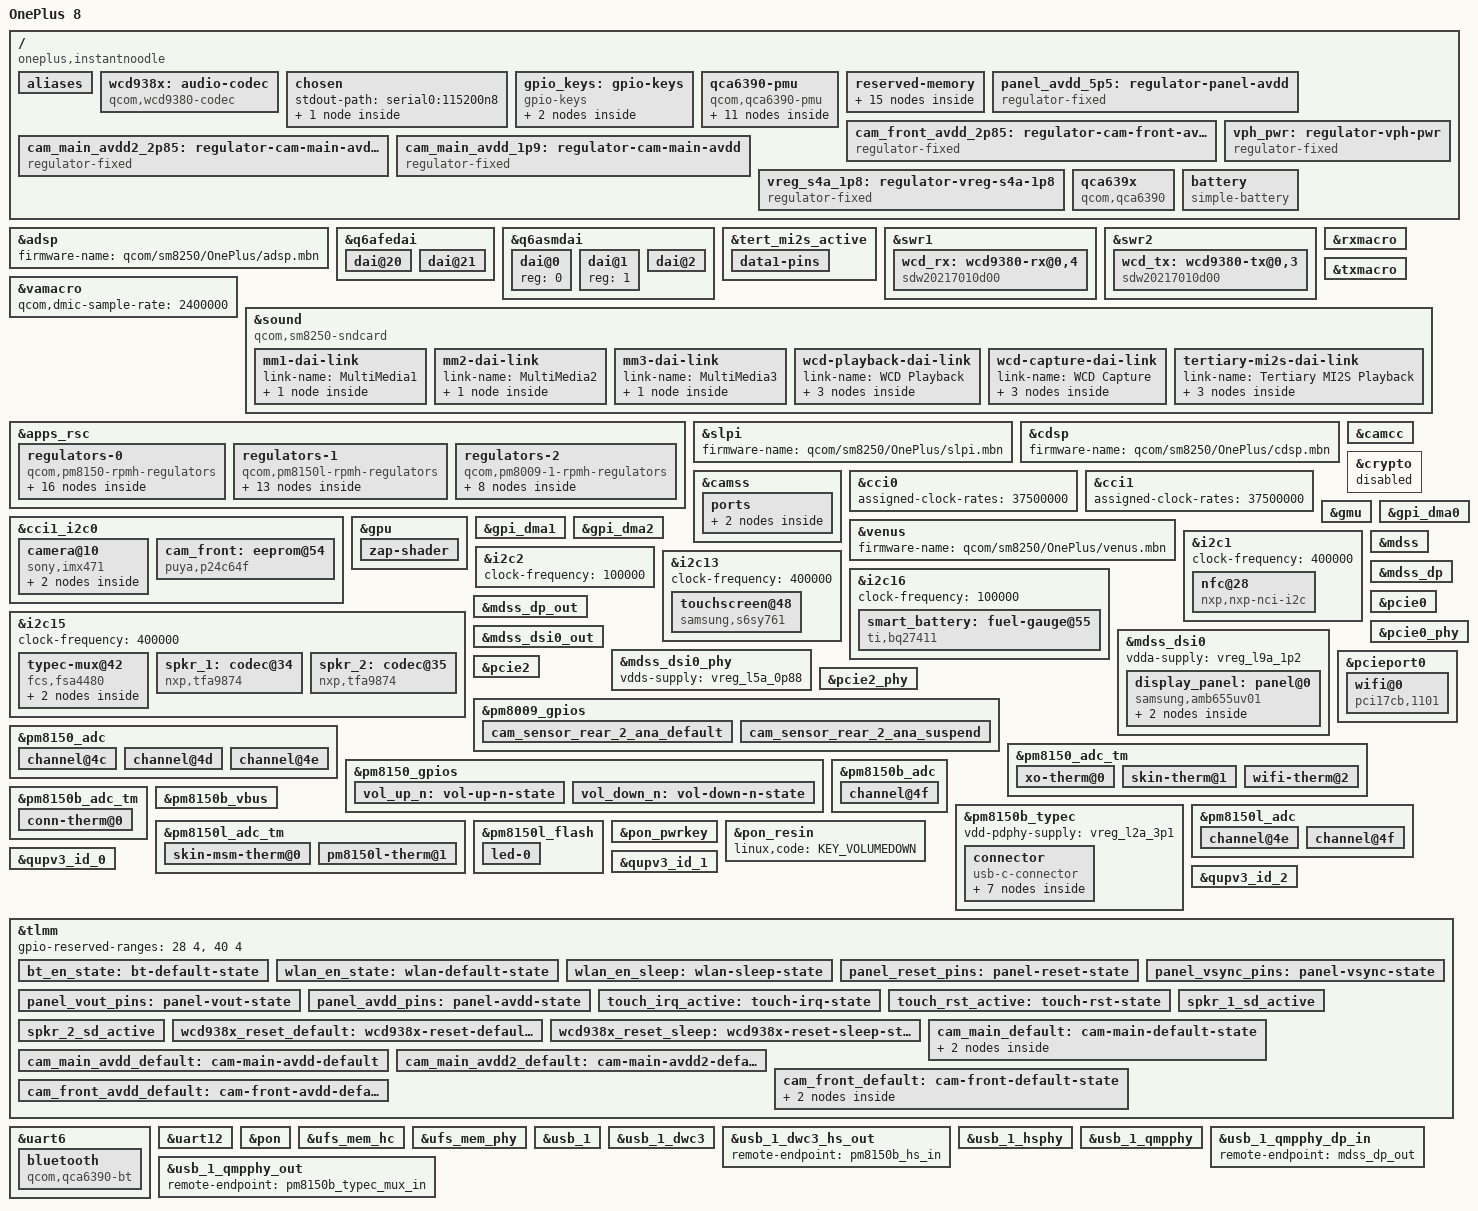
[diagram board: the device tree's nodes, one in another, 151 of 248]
// SPDX-License-Identifier: GPL-2.0 OR BSD-3-Clause
/*
 * Copyright (c) 2025, Xiaoou <xo666@postmarketos.org>
 */

/dts-v1/;

#include <dt-bindings/gpio/gpio.h>
#include <dt-bindings/arm/qcom,ids.h>
#include <dt-bindings/phy/phy.h>
#include <dt-bindings/leds/common.h>
#include <dt-bindings/media/video-interfaces.h>
#include <dt-bindings/regulator/qcom,rpmh-regulator.h>
#include <dt-bindings/sound/qcom,q6afe.h>
#include <dt-bindings/sound/qcom,q6asm.h>
#include <dt-bindings/sound/qcom,q6dsp-lpass-ports.h>
#include <dt-bindings/usb/pd.h>
#include "sm8250.dtsi"
#include "pm8150.dtsi"
#include "pm8150b.dtsi"
#include "pm8150l.dtsi"
#include "pm8009.dtsi"

/* removed_mem @ 0x80b00000 is bigger so we gotta shift everything up... */
/delete-node/ &removed_mem;
/delete-node/ &camera_mem;
/delete-node/ &wlan_mem;
/delete-node/ &ipa_fw_mem;
/delete-node/ &ipa_gsi_mem;
/delete-node/ &gpu_mem;
/delete-node/ &npu_mem;
/delete-node/ &video_mem;
/delete-node/ &cvp_mem;
/delete-node/ &cdsp_mem;
/delete-node/ &slpi_mem;
/delete-node/ &adsp_mem;
/delete-node/ &spss_mem;
/delete-node/ &cdsp_secure_heap;


/ {
	model = "OnePlus 8";
	compatible = "oneplus,instantnoodle", "qcom,kona", "qcom,sm8250";
	chassis-type = "handset";

	qcom,msm-id = <0x164 0x10000>, <0x164 0x20001>;
	qcom,board-id = <0x08 0x00>, <0x00 0x00>;

	aliases {
		serial0 = &uart12;
		serial1 = &uart6;
	};

	wcd938x: audio-codec {
		compatible = "qcom,wcd9380-codec";
		
		pinctrl-names = "default";
		pinctrl-0 = <&wcd938x_reset_default>;
		
		reset-gpios = <&tlmm 32 GPIO_ACTIVE_LOW>;

		vdd-buck-supply = <&vreg_s4a_1p8>;
		vdd-rxtx-supply = <&vreg_s4a_1p8>;
		vdd-io-supply = <&vreg_s4a_1p8>;
		vdd-mic-bias-supply = <&vreg_bob>;

		qcom,micbias1-microvolt = <1800000>;
		qcom,micbias2-microvolt = <1800000>;
		qcom,micbias3-microvolt = <1800000>;
		qcom,micbias4-microvolt = <1800000>;
		qcom,mbhc-buttons-vthreshold-microvolt = <75000 150000 237000 500000 500000 500000 500000 500000>;
		qcom,mbhc-headset-vthreshold-microvolt = <1700000>;
		qcom,mbhc-headphone-vthreshold-microvolt = <50000>;
		qcom,rx-device = <&wcd_rx>;
		qcom,tx-device = <&wcd_tx>;

		#sound-dai-cells = <1>;
	};

	chosen {
		#address-cells = <2>;
		#size-cells = <2>;
		ranges;

		stdout-path = "serial0:115200n8";

		framebuffer: framebuffer@9c000000 {
			compatible = "simple-framebuffer";
			reg = <0 0x9c000000 0 0x2300000>;
			width = <1080>;
			height = <2400>;
			stride = <(1080 * 4)>;
			format = "a8r8g8b8";
		};
	};

	gpio_keys: gpio-keys {
		compatible = "gpio-keys";

		vol-up {
			label = "Volume Up";
			gpios = <&pm8150_gpios 6 GPIO_ACTIVE_LOW>;
			linux,code = <KEY_VOLUMEUP>;
			debounce-interval = <15>;
			linux,can-disable;
			gpio-key,wakeup;
		};

		vol-down {
			label = "Volume Down";
			linux,code = <KEY_VOLUMEDOWN>;
			gpios = <&pm8150_gpios 7 GPIO_ACTIVE_LOW>;
			debounce-interval = <15>;
			linux,can-disable;
			gpio-key,wakeup;
		};
	};

	qca6390-pmu {
		compatible = "qcom,qca6390-pmu";

		pinctrl-names = "default";
		pinctrl-0 = <&bt_en_state>, <&wlan_en_state>;

		vddaon-supply = <&vreg_s6a_0p95>;
		vddpmu-supply = <&vreg_s2f_0p95>;
		vddrfa0p95-supply = <&vreg_s2f_0p95>;
		vddrfa1p3-supply = <&vreg_s8c_1p3>;
		vddrfa1p9-supply = <&vreg_s5a_1p9>;
		vddpcie1p3-supply = <&vreg_s8c_1p3>;
		vddpcie1p9-supply = <&vreg_s5a_1p9>;
		vddio-supply = <&vreg_s4a_1p8>;

		wlan-enable-gpios = <&tlmm 20 GPIO_ACTIVE_HIGH>;
		bt-enable-gpios = <&tlmm 21 GPIO_ACTIVE_HIGH>;

		regulators {
			vreg_pmu_rfa_cmn: ldo0 {
				regulator-name = "vreg_pmu_rfa_cmn";
			};

			vreg_pmu_aon_0p59: ldo1 {
				regulator-name = "vreg_pmu_aon_0p59";
			};

			vreg_pmu_wlcx_0p8: ldo2 {
				regulator-name = "vreg_pmu_wlcx_0p8";
			};

			vreg_pmu_wlmx_0p85: ldo3 {
				regulator-name = "vreg_pmu_wlmx_0p85";
			};

			vreg_pmu_btcmx_0p85: ldo4 {
				regulator-name = "vreg_pmu_btcmx_0p85";
			};

			vreg_pmu_rfa_0p8: ldo5 {
				regulator-name = "vreg_pmu_rfa_0p8";
			};

			vreg_pmu_rfa_1p2: ldo6 {
				regulator-name = "vreg_pmu_rfa_1p2";
			};

			vreg_pmu_rfa_1p7: ldo7 {
				regulator-name = "vreg_pmu_rfa_1p7";
			};

			vreg_pmu_pcie_0p9: ldo8 {
				regulator-name = "vreg_pmu_pcie_0p9";
			};

			vreg_pmu_pcie_1p8: ldo9 {
				regulator-name = "vreg_pmu_pcie_1p8";
			};
		};
	};

	reserved-memory {
		camera_mem: camera@8dc00000 {
			reg = <0x0 0x8dc00000 0x0 0x500000>;
			no-map;
		};

		wlan_mem: wlan@8e100000 {
			reg = <0x0 0x8e100000 0x0 0x100000>;
			no-map;
		};

		ipa_fw_mem: ipa-fw@8e200000 {
			reg = <0x0 0x8e200000 0x0 0x10000>;
			no-map;
		};

		ipa_gsi_mem: ipa-gsi@8e210000 {
			reg = <0x0 0x8e210000 0x0 0xa000>;
			no-map;
		};

		gpu_mem: gpu@8e21a000 {
			reg = <0x0 0x8e21a000 0x0 0x2000>;
			no-map;
		};

		npu_mem: memory@8e300000 {
			reg = <0x0 0x8e300000 0x0 0x500000>;
			no-map;
		};

		video_mem: video@8e800000 {
			reg = <0x0 0x8e800000 0x0 0x500000>;
			no-map;
		};

		cvp_mem: cvp@8ed00000 {
			reg = <0x0 0x8ed00000 0x0 0x500000>;
			no-map;
		};

		cdsp_mem: cdsp@8f200000 {
			reg = <0x0 0x8f200000 0x0 0x1400000>;
			no-map;
		};

		slpi_mem: slpi@90600000 {
			reg = <0x0 0x90600000 0x0 0x1500000>;
			no-map;
		};

		adsp_mem: adsp@91b00000 {
			reg = <0x00 0x91b00000 0x00 0x2500000>;
			no-map;
		};

		spss_mem: spss@94000000 {
			reg = <0x0 0x94000000 0x0 0x100000>;
			no-map;
		};

		cdsp_secure_heap: cdsp-secure@94100000 {
			reg = <0x0 0x94100000 0x0 0x4600000>;
			no-map;
		};

		framebuffer@9c000000 {
			reg = <0 0x9c000000 0 0x2300000>;
			no-map;
		};
		
		ramoops: ramoops@B0000000 {
		        compatible = "ramoops";
		        reg = <0 0xB0000000 0 0x00400000>;
		        record-size = <0x40000>; //256x1024
		        console-size = <0x40000>;
		        ftrace-size = <0x40000>;
		        pmsg-size= <0x200000>;
		        devinfo-size= <0x01000>;
		        ecc-size= <0x0>;
		};
	};

	panel_avdd_5p5: regulator-panel-avdd {
		compatible = "regulator-fixed";
		regulator-name = "panel_avdd_5p5";
		regulator-min-microvolt = <5500000>;
		regulator-max-microvolt = <5500000>;
		regulator-enable-ramp-delay = <233>;
		gpio = <&tlmm 61 GPIO_ACTIVE_HIGH>;
		regulator-boot-on;
		pinctrl-names = "default";
		pinctrl-0 = <&panel_avdd_pins>;
	};
	
	cam_front_avdd_2p85: regulator-cam-front-avdd {
		compatible = "regulator-fixed";
		regulator-name = "cam_front_avdd_2p85";
		regulator-min-microvolt = <2856000>;
		regulator-max-microvolt = <2856000>;
		gpio = <&tlmm 24 GPIO_ACTIVE_HIGH>;
		regulator-enable-ramp-delay = <135>;
		enable-active-high;
		regulator-always-on;
		pinctrl-names = "default";
		pinctrl-0 = <&cam_front_avdd_default>;
	};
	
	cam_main_avdd2_2p85: regulator-cam-main-avdd2 {
		compatible = "regulator-fixed";
		regulator-name = "cam_main_avdd2_2p85";
		regulator-min-microvolt = <2856000>;
		regulator-max-microvolt = <2856000>;
		gpio = <&tlmm 156 GPIO_ACTIVE_HIGH>;
		regulator-enable-ramp-delay = <135>;
		enable-active-high;
		regulator-always-on;
		pinctrl-names = "default";
		pinctrl-0 = <&cam_main_avdd2_default>;
	};
	
	cam_main_avdd_1p9: regulator-cam-main-avdd {
		compatible = "regulator-fixed";
		regulator-name = "cam_main_avdd_1p9";
		regulator-min-microvolt = <1900000>;
		regulator-max-microvolt = <1900000>;
		gpio = <&tlmm 26 GPIO_ACTIVE_HIGH>;
		regulator-enable-ramp-delay = <135>;
		enable-active-high;
		regulator-always-on;
		pinctrl-names = "default";
		pinctrl-0 = <&cam_main_avdd_default>;
	};
	
	vph_pwr: regulator-vph-pwr {
		compatible = "regulator-fixed";
		regulator-name = "vph_pwr";
		regulator-min-microvolt = <3700000>;
		regulator-max-microvolt = <3700000>;
		regulator-always-on;
	};

	vreg_s4a_1p8: regulator-vreg-s4a-1p8 {
		compatible = "regulator-fixed";
		regulator-name = "vreg_s4a_1p8";
		regulator-min-microvolt = <1800000>;
		regulator-max-microvolt = <1800000>;
		regulator-always-on;
	};

	qca639x: qca639x {
		compatible = "qcom,qca6390";
		#power-domain-cells = <0>;
 
		vddaon-supply = <&vreg_s6a_0p95>;
		vddpmu-supply = <&vreg_s2f_0p95>;
		vddrfa1-supply = <&vreg_s2f_0p95>;
		vddrfa2-supply = <&vreg_s8c_1p3>;
		vddrfa3-supply = <&vreg_s5a_1p9>;
		vddpcie1-supply = <&vreg_s8c_1p3>;
		vddpcie2-supply = <&vreg_s5a_1p9>;
		vddio-supply = <&vreg_s4a_1p8>;

		pinctrl-names = "default", "sleep";
		pinctrl-0 = <&wlan_en_state>;
		pinctrl-1 = <&wlan_en_sleep>;
 
		wlan-en-gpios = <&tlmm 20 GPIO_ACTIVE_HIGH>;
	};
	
	battery: battery {
		compatible = "simple-battery";
		energy-full-design-microwatt-hours = <16370000>;
		charge-full-design-microamp-hours = <4270000>;
		voltage-min-design-microvolt = <3400000>;
		voltage-max-design-microvolt = <4435000>;
	};
};

&adsp {
	firmware-name = "qcom/sm8250/OnePlus/adsp.mbn";
	status = "okay";
};
			
&q6afedai {
	dai@20 {
		reg = <TERTIARY_MI2S_RX>;
		qcom,sd-lines = <1>;
	};

	dai@21 {
		reg = <TERTIARY_MI2S_TX>;
		qcom,sd-lines = <0>;
	};
};

&q6asmdai {
	dai@0 {
		reg = <0>;
	};

	dai@1 {
		reg = <1>;
	};

        dai@2 {
		reg = <2>;
		is-compress-dai;
	};
};


&tert_mi2s_active {
	data1-pins {
		pins = "gpio137";
		function = "mi2s2_data1";
		drive-strength = <8>;
		output-high;
	};
};

&swr1 {
	status = "okay";

	wcd_rx: wcd9380-rx@0,4 {
		compatible = "sdw20217010d00";
		reg = <0 4>;
		qcom,rx-port-mapping = <1 2 3 4 5>;
	};
};

&swr2 {
	status = "okay";

	wcd_tx: wcd9380-tx@0,3 {
		compatible = "sdw20217010d00";
		reg = <0 3>;
		qcom,tx-port-mapping = <2 3 4 5>;
	};
};

&rxmacro {
	status = "okay";
};
	
&txmacro {
	status = "okay";
};

&vamacro {
	status = "okay";
	qcom,dmic-sample-rate = <2400000>;
};

&sound {
	compatible = "qcom,sm8250-sndcard";
	pinctrl-names = "default";
	pinctrl-0 = <&tert_mi2s_active>;
	model = "OnePlus8";
	
	audio-routing = 
		"IN1_HPHL", "HPHL_OUT",
		"IN2_HPHR", "HPHR_OUT",
		"AMIC1", "MIC BIAS1",
		"AMIC2", "MIC BIAS2",
		"AMIC3", "MIC BIAS3",
		"AMIC4", "MIC BIAS3",
		"AMIC5", "MIC BIAS4",
		"TX SWR_ADC0", "ADC1_OUTPUT",
		"TX SWR_ADC1", "ADC2_OUTPUT",
		"TX SWR_ADC2", "ADC3_OUTPUT",
		"TX SWR_ADC3", "ADC4_OUTPUT",
		"TX SWR_DMIC0", "DMIC1_OUTPUT",
		"TX SWR_DMIC1", "DMIC2_OUTPUT",
		"TX SWR_DMIC2", "DMIC3_OUTPUT",
		"TX SWR_DMIC3", "DMIC4_OUTPUT",
		"TX SWR_DMIC4", "DMIC5_OUTPUT",
		"TX SWR_DMIC5", "DMIC6_OUTPUT",
		"TX SWR_DMIC6", "DMIC7_OUTPUT",
		"TX SWR_DMIC7", "DMIC8_OUTPUT";

	mm1-dai-link {
		link-name = "MultiMedia1";
		cpu {
			sound-dai = <&q6asmdai MSM_FRONTEND_DAI_MULTIMEDIA1>;
		};
	};

	mm2-dai-link {
		link-name = "MultiMedia2";
		cpu {
			sound-dai = <&q6asmdai MSM_FRONTEND_DAI_MULTIMEDIA2>;
		};
	};

	mm3-dai-link {
		link-name = "MultiMedia3";
		cpu {
			sound-dai = <&q6asmdai MSM_FRONTEND_DAI_MULTIMEDIA3>;
		};
	};

	wcd-playback-dai-link {
		link-name = "WCD Playback";
		cpu {
			sound-dai = <&q6afedai RX_CODEC_DMA_RX_0>;
		};
		codec {
			sound-dai = <&wcd938x 0>, <&swr1 0>, <&rxmacro 0>;
		};
		platform {
			sound-dai = <&q6routing>;
		};
	};

	wcd-capture-dai-link {
		link-name = "WCD Capture";
		cpu {
			sound-dai = <&q6afedai TX_CODEC_DMA_TX_3>;
		};

		codec {
			sound-dai = <&wcd938x 1>, <&swr2 0>, <&txmacro 0>;
		};
		platform {
			sound-dai = <&q6routing>;
		};
	};

	tertiary-mi2s-dai-link {
		link-name = "Tertiary MI2S Playback";
		cpu {
			sound-dai = <&q6afedai TERTIARY_MI2S_RX>;
		};

		platform {
			sound-dai = <&q6routing>;
		};
		
		codec {
			sound-dai = <&spkr_1>, <&spkr_2>;
		};
	};
};

&apps_rsc {
	regulators-0 {
		compatible = "qcom,pm8150-rpmh-regulators";
		qcom,pmic-id = "a";

		vdd-s1-supply = <&vph_pwr>;
		vdd-s2-supply = <&vph_pwr>;
		vdd-s3-supply = <&vph_pwr>;
		vdd-s4-supply = <&vph_pwr>;
		vdd-s5-supply = <&vph_pwr>;
		vdd-s6-supply = <&vph_pwr>;
		vdd-s7-supply = <&vph_pwr>;
		vdd-s8-supply = <&vph_pwr>;
		vdd-s9-supply = <&vph_pwr>;
		vdd-s10-supply = <&vph_pwr>;
		vdd-l2-l10-supply = <&vreg_bob>;
		vdd-l3-l4-l5-l18-supply = <&vreg_s6a_0p95>;
		vdd-l6-l9-supply = <&vreg_s8c_1p3>;
		vdd-l7-l12-l14-l15-supply = <&vreg_s5a_1p9>;
		vdd-l13-l16-l17-supply = <&vreg_bob>;

		vreg_s5a_1p9: smps5 {
			regulator-name = "vreg_s5a_1p9";
			regulator-min-microvolt = <1824000>;
			regulator-max-microvolt = <2040000>;
			regulator-initial-mode = <RPMH_REGULATOR_MODE_HPM>;
			regulator-always-on;
		};

		vreg_s6a_0p95: smps6 {
			regulator-name = "vreg_s6a_0p95";
			regulator-min-microvolt = <920000>;
			regulator-max-microvolt = <1128000>;
			regulator-initial-mode = <RPMH_REGULATOR_MODE_HPM>;
		};

		vreg_l2a_3p1: ldo2 {
			regulator-name = "vreg_l2a_3p1";
			regulator-min-microvolt = <3072000>;
			regulator-max-microvolt = <3072000>;
			regulator-initial-mode = <RPMH_REGULATOR_MODE_HPM>;
		};

		vreg_l3a_0p9: ldo3 {
			regulator-name = "vreg_l3a_0p9";
			regulator-min-microvolt = <928000>;
			regulator-max-microvolt = <932000>;
			regulator-initial-mode = <RPMH_REGULATOR_MODE_HPM>;
		};

		/* l4 = VDD_SSC_MX (lmx.lvl) */

		vreg_l5a_0p88: ldo5 {
			regulator-name = "vreg_l5a_0p88";
			regulator-min-microvolt = <880000>;
			regulator-max-microvolt = <880000>;
			regulator-initial-mode = <RPMH_REGULATOR_MODE_HPM>;
		};

		vreg_l6a_1p2: ldo6 {
			regulator-name = "vreg_l6a_1p2";
			regulator-min-microvolt = <1200000>;
			regulator-max-microvolt = <1200000>;
			regulator-initial-mode = <RPMH_REGULATOR_MODE_HPM>;
			regulator-allow-set-load;
			regulator-allowed-modes = <RPMH_REGULATOR_MODE_LPM
						   RPMH_REGULATOR_MODE_HPM>;
		};

		vreg_l7a_1p7: ldo7 {
			regulator-name = "vreg_l7a_1p7";
			regulator-min-microvolt = <1704000>;
			regulator-max-microvolt = <1800000>;
			regulator-initial-mode = <RPMH_REGULATOR_MODE_HPM>;
		};

		vreg_l9a_1p2: ldo9 {
			regulator-name = "vreg_l9a_1p2";
			regulator-min-microvolt = <1200000>;
			regulator-max-microvolt = <1200000>;
			regulator-initial-mode = <RPMH_REGULATOR_MODE_HPM>;
		};

		vreg_l10a_1p8: ldo10 {
			regulator-name = "vreg_l10a_1p8";
			regulator-min-microvolt = <1800000>;
			regulator-max-microvolt = <2960000>;
			regulator-initial-mode = <RPMH_REGULATOR_MODE_HPM>;
		};

		/* l11 = VDD_SSC_CX (lxc.lvl) */

		vreg_l12a_1p8: ldo12 {
			regulator-name = "vreg_l12a_1p8";
			regulator-min-microvolt = <1800000>;
			regulator-max-microvolt = <1800000>;
			regulator-initial-mode = <RPMH_REGULATOR_MODE_HPM>;
		};

		vreg_l13a_ts_3p0: ldo13 {
			regulator-name = "vreg_l13a_ts_3p0";
			regulator-min-microvolt = <3008000>;
			regulator-max-microvolt = <3008000>;
			regulator-initial-mode = <RPMH_REGULATOR_MODE_HPM>;
		};

		vreg_l14a_1p8: ldo14 {
			regulator-name = "vreg_l14a_1p8";
			regulator-min-microvolt = <1650000>;
			regulator-max-microvolt = <1880000>;
			regulator-initial-mode = <RPMH_REGULATOR_MODE_LPM>;
			regulator-boot-on;
		};

		vreg_l15a_1p8: ldo15 {
			regulator-name = "vreg_l15a_1p8";
			regulator-min-microvolt = <1800000>;
			regulator-max-microvolt = <1800000>;
			regulator-initial-mode = <RPMH_REGULATOR_MODE_HPM>;
		};

		/* Fingerprint reader power (goodix_fp) */
		vreg_l16a_2p7: ldo16 {
			regulator-name = "vreg_l16a_2p7";
			regulator-min-microvolt = <3024000>;
			regulator-max-microvolt = <3304000>;
			regulator-initial-mode = <RPMH_REGULATOR_MODE_HPM>;
		};

		vreg_l17a_3p0: ldo17 {
			regulator-name = "vreg_l17a_3p0";
			regulator-min-microvolt = <2504000>;
			regulator-max-microvolt = <2950000>;
			regulator-initial-mode = <RPMH_REGULATOR_MODE_HPM>;
			regulator-allow-set-load;
			regulator-allowed-modes = <RPMH_REGULATOR_MODE_LPM
						   RPMH_REGULATOR_MODE_HPM>;
		};

		vreg_l18a_0p92: ldo18 {
			regulator-name = "vreg_l18a_0p92";
			regulator-min-microvolt = <800000>;
			regulator-max-microvolt = <920000>;
			regulator-initial-mode = <RPMH_REGULATOR_MODE_HPM>;
		};
	};

	regulators-1 {
		compatible = "qcom,pm8150l-rpmh-regulators";
		qcom,pmic-id = "c";

		vdd-s1-supply = <&vph_pwr>;
		vdd-s2-supply = <&vph_pwr>;
		vdd-s3-supply = <&vph_pwr>;
		vdd-s4-supply = <&vph_pwr>;
		vdd-s5-supply = <&vph_pwr>;
		vdd-s6-supply = <&vph_pwr>;
		vdd-s7-supply = <&vph_pwr>;
		vdd-s8-supply = <&vph_pwr>;
		vdd-l1-l8-supply = <&vreg_s4a_1p8>;
		vdd-l2-l3-supply = <&vreg_s8c_1p3>;
		vdd-l4-l5-l6-supply = <&vreg_bob>;
		vdd-l7-l11-supply = <&vreg_bob>;
		vdd-l9-l10-supply = <&vreg_bob>;
		vdd-bob-supply = <&vph_pwr>;

		vreg_s8c_1p3: smps8 {
			regulator-name = "vreg_s8c_1p3";
			regulator-min-microvolt = <1200000>;
			regulator-max-microvolt = <1400000>;
			regulator-initial-mode = <RPMH_REGULATOR_MODE_HPM>;
		};

		vreg_bob: bob {
			regulator-name = "vreg_bob";
			regulator-min-microvolt = <3008000>;
			regulator-max-microvolt = <3960000>;
			regulator-initial-mode = <RPMH_REGULATOR_MODE_AUTO>;
			regulator-always-on;
		};

		vreg_l1c_1p8: ldo1 {
			regulator-name = "vreg_l1c_1p8";
			regulator-min-microvolt = <1800000>;
			regulator-max-microvolt = <1800000>;
			regulator-initial-mode = <RPMH_REGULATOR_MODE_HPM>;
		};

		vreg_l2c_1p2: ldo2 {
			regulator-name = "vreg_l2c_1p2";
			regulator-min-microvolt = <1200000>;
			regulator-max-microvolt = <1304000>;
			regulator-initial-mode = <RPMH_REGULATOR_MODE_HPM>;
		};

		vreg_l3c_0p8: ldo3 {
			regulator-name = "vreg_l3c_0p8";
			regulator-min-microvolt = <800000>;
			regulator-max-microvolt = <1200000>;
			regulator-initial-mode = <RPMH_REGULATOR_MODE_HPM>;
		};

		vreg_l4c_1p7: ldo4 {
			regulator-name = "vreg_l4c_1p7";
			regulator-min-microvolt = <1800000>;
			regulator-max-microvolt = <2800000>;
			regulator-initial-mode = <RPMH_REGULATOR_MODE_HPM>;
		};

		vreg_l5c_1p8: ldo5 {
			regulator-name = "vreg_l5c_1p8";
			regulator-min-microvolt = <1800000>;
			regulator-max-microvolt = <2800000>;
			regulator-initial-mode = <RPMH_REGULATOR_MODE_HPM>;
		};

		vreg_l6c_2p96: ldo6 {
			regulator-name = "vreg_l6c_2p96";
			regulator-min-microvolt = <1800000>;
			regulator-max-microvolt = <2960000>;
			regulator-initial-mode = <RPMH_REGULATOR_MODE_HPM>;
		};

		vreg_l7c_cam_vcm0_2p85: ldo7 {
			regulator-name = "vreg_l7c_cam_vcm0_2p85";
			regulator-min-microvolt = <2856000>;
			regulator-max-microvolt = <3104000>;
			regulator-initial-mode = <RPMH_REGULATOR_MODE_HPM>;
			regulator-always-on;
		};

		vreg_l8c_1p8: ldo8 {
			regulator-name = "vreg_l8c_1p8";
			regulator-min-microvolt = <1800000>;
			regulator-max-microvolt = <1800000>;
			regulator-initial-mode = <RPMH_REGULATOR_MODE_HPM>;
		};

		vreg_l9c_2p96: ldo9 {
			regulator-name = "vreg_l9c_2p96";
			regulator-min-microvolt = <2704000>;
			regulator-max-microvolt = <2960000>;
			regulator-initial-mode = <RPMH_REGULATOR_MODE_HPM>;
		};

		vreg_l10c_3p0: ldo10 {
			regulator-name = "vreg_l10c_3p0";
			regulator-min-microvolt = <3000000>;
			regulator-max-microvolt = <3312000>;
			regulator-initial-mode = <RPMH_REGULATOR_MODE_HPM>;
		};

		vreg_l11c_3p3: ldo11 {
			regulator-name = "vreg_l11c_3p3";
			regulator-min-microvolt = <2900000>;
			regulator-max-microvolt = <3304000>;
			regulator-initial-mode = <RPMH_REGULATOR_MODE_HPM>;
			regulator-boot-on;
			/* FIXME: we don't yet support power cycling the panel */
			//regulator-always-on;
		};
	};
	
	regulators-2 {
		compatible = "qcom,pm8009-1-rpmh-regulators";
		qcom,pmic-id = "f";

		vdd-s1-supply = <&vph_pwr>;
		vdd-s2-supply = <&vph_pwr>;
		vdd-l2-supply = <&vreg_s8c_1p3>;
		vdd-l3-l4-supply = <&vreg_bob>;
		vdd-l5-l6-supply = <&vreg_bob>;
		vdd-l7-supply = <&vreg_s4a_1p8>;

		vreg_s2f_0p95: smps2 {
			regulator-name = "vreg_s2f_0p95";
			regulator-min-microvolt = <900000>;
			regulator-max-microvolt = <952000>;
			regulator-initial-mode = <RPMH_REGULATOR_MODE_AUTO>;
		};

		vreg_l1f_1p1: ldo1 {
			regulator-name = "vreg_l1f_1p1";
			regulator-min-microvolt = <1104000>;
			regulator-max-microvolt = <1104000>;
			regulator-initial-mode = <RPMH_REGULATOR_MODE_HPM>;
			regulator-always-on;
		};

		vreg_l2f_1p2: ldo2 {
			regulator-name = "vreg_l2f_1p2";
			regulator-min-microvolt = <1200000>;
			regulator-max-microvolt = <1200000>;
			regulator-initial-mode = <RPMH_REGULATOR_MODE_HPM>;
			regulator-always-on;
		};
		
		vreg_l3f_1p05: ldo3 {
			regulator-name = "vreg_l3f_1p05";
			regulator-min-microvolt = <1056000>;
			regulator-max-microvolt = <1056000>;
			regulator-initial-mode = <RPMH_REGULATOR_MODE_HPM>;
			regulator-always-on;
		};

		vreg_l4f_1p05: ldo4 {
			regulator-name = "vreg_l4f_1p05";
			regulator-min-microvolt = <1056000>;
			regulator-max-microvolt = <1056000>;
			regulator-initial-mode = <RPMH_REGULATOR_MODE_HPM>;
			regulator-always-on;
		};

		vreg_l5f_2p8: ldo5 {
			regulator-name = "vreg_l5f_2p8";
			regulator-min-microvolt = <2800000>;
			regulator-max-microvolt = <3000000>;
			regulator-initial-mode = <RPMH_REGULATOR_MODE_HPM>;
			regulator-always-on;
		};

		vreg_l6f_2p8: ldo6 {
			regulator-name = "vreg_l6f_2p8";
			regulator-min-microvolt = <2800000>;
			regulator-max-microvolt = <2800000>;
			regulator-initial-mode = <RPMH_REGULATOR_MODE_HPM>;
			regulator-always-on;
		};

		vreg_l7f_1p8: ldo7 {
			regulator-name = "vreg_l7f_1p8";
			regulator-min-microvolt = <1800000>;
			regulator-max-microvolt = <1800000>;
			regulator-initial-mode = <RPMH_REGULATOR_MODE_HPM>;
			regulator-always-on;
		};
	};
};

&slpi {
	firmware-name = "qcom/sm8250/OnePlus/slpi.mbn";
	status = "okay";
};

&cdsp {
	firmware-name = "qcom/sm8250/OnePlus/cdsp.mbn";
	status = "okay";
};

&camcc {
	status = "okay";
};

&camss {
	vdda-phy-supply = <&vreg_l5a_0p88>;
	vdda-pll-supply = <&vreg_l9a_1p2>;

	status = "okay";
	
	ports {
		port@2 {
			csiphy2_ep: endpoint {
			clock-lanes = <7>;
			data-lanes = <0 1 2 3>;
			bus-type = <MEDIA_BUS_TYPE_CSI2_DPHY>;
			remote-endpoint = <&cam_imx471_ep>;
			};
		};
	};
};

&cci0 {
	status = "okay";
	assigned-clock-rates = <37500000>;
};

&cci1 {
	status = "okay";
	assigned-clock-rates = <37500000>;
};

&cci1_i2c0 {
	camera@10 {
		compatible = "sony,imx471";
		reg = <0x10>;
		
		clocks = <&camcc CAM_CC_MCLK2_CLK>;
		clock-names = "mclk";
		clock-frequency = <19200000>;
		assigned-clocks = <&camcc CAM_CC_MCLK2_CLK>;
		assigned-clock-rates = <19200000>;

		vio-supply = <&vreg_l7f_1p8>;
		vdig-supply = <&vreg_l3f_1p05>;
		vana-supply = <&cam_front_avdd_2p85>;
		
		power-domains = <&camcc TITAN_TOP_GDSC>;

		reset-gpios = <&tlmm 90 GPIO_ACTIVE_LOW>;
	
		pinctrl-names = "default";
		pinctrl-0 = <&cam_front_default>;

		orientation = <0>;
		rotation = <270>;

		port {
			cam_imx471_ep: endpoint {
			data-lanes = <1 2 3 4>;
			link-frequencies = /bits/ 64 <600000000>;
			remote-endpoint = <&csiphy2_ep>;
			};
		};
	};
	
	cam_front: eeprom@54 {
		compatible = "puya,p24c64f",
			     "atmel,24c64";
		reg = <0x54>;
		vcc-supply = <&vreg_l7f_1p8>;
		read-only;
	};
};

&crypto {
	status = "disabled";
};

&gmu {
	status = "okay";
};

&gpu {
	status = "okay";

	zap-shader {
		memory-region = <&gpu_mem>;
		firmware-name = "qcom/sm8250/OnePlus/a650_zap.mbn";
	};
};

&venus {
	status = "okay";
	firmware-name = "qcom/sm8250/OnePlus/venus.mbn";
};

&gpi_dma0 {
	status = "okay";
};

&gpi_dma1 {
	status = "okay";
};

&gpi_dma2 {
	status = "okay";
};

&i2c1 {
    status = "okay";
    clock-frequency = <400000>;

    nfc@28 {
        compatible = "nxp,nxp-nci-i2c";
        reg = <0x28>;

        interrupt-parent = <&tlmm>;
        interrupts = <111 IRQ_TYPE_LEVEL_HIGH>;

        enable-gpios = <&tlmm 83 GPIO_ACTIVE_HIGH>,
                        <&tlmm 110 GPIO_ACTIVE_HIGH>;
    };
};

&i2c2 {
	clock-frequency = <100000>;
	status = "okay";
};

&i2c13 {
	clock-frequency = <400000>;
	status = "okay";
	
	touchscreen@48 {
		compatible = "samsung,s6sy761";
		reg = <0x48>;
		interrupt-parent = <&tlmm>;
		interrupts = <39 IRQ_TYPE_LEVEL_HIGH>;

		avdd-supply = <&vreg_l13a_ts_3p0>;
		vdd-supply = <&vreg_l1c_1p8>;
		
		touchscreen-size-x = <1080>;
		touchscreen-size-y = <2400>;
		
		pinctrl-names = "default";
		pinctrl-0 = <&touch_irq_active &touch_rst_active>;
	};
};


&i2c15 {
	status = "okay";
	clock-frequency = <400000>;

	typec-mux@42 {
		compatible = "fcs,fsa4480";
		reg = <0x42>;

		vcc-supply = <&vreg_s4a_1p8>;

		mode-switch;
		orientation-switch;

		port {
			fsa4480_sbu_mux: endpoint {
				remote-endpoint = <&pm8150b_typec_sbu_out>;
			};
		};
	};
	
	spkr_1: codec@34 {
		compatible = "nxp,tfa9874";
		reg = <0x34>;
		vdd-supply = <&vreg_s4a_1p8>;
		reset-gpio = <&tlmm 91 GPIO_ACTIVE_LOW>;
		pinctrl-names = "default";
		pinctrl-0 = <&spkr_1_sd_active>;
		sound-name-prefix = "SpkrLeft";
		#sound-dai-cells = <0>;
	};
	
	spkr_2: codec@35 {
		compatible = "nxp,tfa9874";
		reg = <0x35>;
		vdd-supply = <&vreg_s4a_1p8>;
		reset-gpio = <&tlmm 99 GPIO_ACTIVE_LOW>;
		pinctrl-names = "default";
		pinctrl-0 = <&spkr_2_sd_active>;
		sound-name-prefix = "SpkrRight";
		is_second_channel;
		#sound-dai-cells = <0>;
	};
};

&i2c16 {
	clock-frequency = <100000>;
	status = "okay";
	#address-cells = <1>;
	#size-cells = <0>;

	smart_battery: fuel-gauge@55 {
		compatible = "ti,bq27411";
		status = "okay";
		reg = <0x55>;
		monitored-battery = <&battery>;
	};
};

&mdss {
	status = "okay";
};

&mdss_dp {
	status = "okay";
};

&mdss_dp_out {
	data-lanes = <0 1>;
	remote-endpoint = <&usb_1_qmpphy_dp_in>;
};

&mdss_dsi0 {
	vdda-supply = <&vreg_l9a_1p2>;
	status = "okay";

	display_panel: panel@0 {
		compatible = "samsung,amb655uv01";
		reg = <0>;
		vddio-supply = <&vreg_l14a_1p8>;
		vdd-supply = <&vreg_l11c_3p3>;
		avdd-supply = <&panel_avdd_5p5>;
		reset-gpios = <&tlmm 75 GPIO_ACTIVE_LOW>;

		pinctrl-0 = <&panel_reset_pins &panel_vsync_pins &panel_vout_pins>;
		pinctrl-names = "default";

		status = "okay";

		port {
			panel_in_0: endpoint {
				remote-endpoint = <&mdss_dsi0_out>;
			};
		};
	};

};

&mdss_dsi0_out {
	data-lanes = <0 1 2 3>;
	remote-endpoint = <&panel_in_0>;
};

&mdss_dsi0_phy {
	vdds-supply = <&vreg_l5a_0p88>;
	status = "okay";
};

&pcie0 {
	vdda-supply = <&vreg_l9a_1p2>;
	vddpe-3v3-supply = <&vreg_l11c_3p3>;
	status = "okay";
};

&pcie0_phy {
	vdda-phy-supply = <&vreg_l5a_0p88>;
	vdda-pll-supply = <&vreg_l9a_1p2>;

	status = "okay";
};

&pcieport0 {
	wifi@0 {
		compatible = "pci17cb,1101";
		reg = <0x10000 0x0 0x0 0x0 0x0>;

		vddrfacmn-supply = <&vreg_pmu_rfa_cmn>;
		vddaon-supply = <&vreg_pmu_aon_0p59>;
		vddwlcx-supply = <&vreg_pmu_wlcx_0p8>;
		vddwlmx-supply = <&vreg_pmu_wlmx_0p85>;
		vddrfa0p8-supply = <&vreg_pmu_rfa_0p8>;
		vddrfa1p2-supply = <&vreg_pmu_rfa_1p2>;
		vddrfa1p7-supply = <&vreg_pmu_rfa_1p7>;
		vddpcie0p9-supply = <&vreg_pmu_pcie_0p9>;
		vddpcie1p8-supply = <&vreg_pmu_pcie_1p8>;
	};
};

&pcie2 {
	vdda-supply = <&vreg_l9a_1p2>;
	vddpe-3v3-supply = <&vreg_l11c_3p3>;
	status = "okay";
};

&pcie2_phy {
	vdda-phy-supply = <&vreg_l5a_0p88>;
	vdda-pll-supply = <&vreg_l9a_1p2>;
	status = "okay";
};

&pm8009_gpios {
	cam_sensor_rear_2_ana_default: cam_sensor_rear_2_ana_default {
		pins = "gpio1";
		function = "normal";
		power-source = <0>;
		output-low;
		input-disable;
	};

	cam_sensor_rear_2_ana_suspend: cam_sensor_rear_2_ana_suspend {
		pins = "gpio1";
		function = "normal";
		power-source = <0>;
		bias-pull-down;
		input-disable;
	};

};

&pm8150_adc {
	channel@4c {
		reg = <ADC5_XO_THERM_100K_PU>;
		qcom,ratiometric;
		qcom,hw-settle-time = <200>;
		label = "xo_therm";
	};

	channel@4d {
		reg = <ADC5_AMUX_THM2_100K_PU>;
		qcom,ratiometric;
		qcom,hw-settle-time = <200>;
		label = "skin_therm";
	};

	channel@4e {
		reg = <ADC5_AMUX_THM2_100K_PU>;
		qcom,ratiometric;
		qcom,hw-settle-time = <200>;
		label = "wifi_therm";
	};
};

&pm8150_adc_tm {
	status = "okay";

	xo-therm@0 {
		reg = <0>;
		io-channels = <&pm8150_adc ADC5_XO_THERM_100K_PU>;
		qcom,ratiometric;
		qcom,hw-settle-time-us = <200>;
	};

	skin-therm@1 {
		reg = <1>;
		io-channels = <&pm8150_adc ADC5_XO_THERM_100K_PU>;
		qcom,ratiometric;
		qcom,hw-settle-time-us = <200>;
	};

	wifi-therm@2 {
		reg = <2>;
		io-channels = <&pm8150_adc ADC5_AMUX_THM2_100K_PU>;
		qcom,ratiometric;
		qcom,hw-settle-time-us = <200>;
	};
};

&pm8150_gpios {
	vol_up_n: vol-up-n-state {
		pins = "gpio6";
		function = "normal";
		power-source = <1>;
		input-enable;
		bias-pull-up;
	};

	vol_down_n: vol-down-n-state {
		pins = "gpio7";
		function = "normal";
		power-source = <1>;
		input-enable;
		bias-pull-up;
	};
};

&pm8150b_adc {
	channel@4f {
		reg = <ADC5_AMUX_THM3_100K_PU>;
		qcom,ratiometric;
		qcom,hw-settle-time = <200>;
		label = "conn_therm";
	};
};

&pm8150b_adc_tm {
	status = "okay";

	conn-therm@0 {
		reg = <0>;
		io-channels = <&pm8150b_adc ADC5_AMUX_THM3_100K_PU>;
		qcom,ratiometric;
		qcom,hw-settle-time-us = <200>;
	};
};

&pm8150b_typec {
	vdd-pdphy-supply = <&vreg_l2a_3p1>;
	status = "okay";

	connector {
		compatible = "usb-c-connector";

		op-sink-microwatt = <10000000>;
		power-role = "dual";
		data-role = "dual";
		self-powered;

		source-pdos = <PDO_FIXED(5000, 3000,
					 PDO_FIXED_DUAL_ROLE |
					 PDO_FIXED_USB_COMM |
					 PDO_FIXED_DATA_SWAP)>;

		sink-pdos = <PDO_FIXED(5000, 3000,
				       PDO_FIXED_DUAL_ROLE |
				       PDO_FIXED_USB_COMM |
				       PDO_FIXED_DATA_SWAP)
				       PDO_VAR(5000, 12000, 5000)>;

		ports {
			#address-cells = <1>;
			#size-cells = <0>;

			port@0 {
				reg = <0>;

				pm8150b_hs_in: endpoint {
					remote-endpoint = <&usb_1_dwc3_hs_out>;
				};
			};

			port@1 {
				reg = <1>;

				pm8150b_typec_mux_in: endpoint {
					remote-endpoint = <&usb_1_qmpphy_out>;
				};
			};

			port@2 {
				reg = <2>;

				pm8150b_typec_sbu_out: endpoint {
					remote-endpoint = <&fsa4480_sbu_mux>;
				};
			};
		};
	};
};

&pm8150b_vbus {
	regulator-min-microamp = <500000>;
	regulator-max-microamp = <3000000>;
	status = "okay";
};

&pm8150l_adc {
	channel@4e {
		reg = <ADC5_AMUX_THM2_100K_PU>;
		qcom,ratiometric;
		qcom,hw-settle-time = <200>;
		label = "skin_msm_therm";
	};

	channel@4f {
		reg = <ADC5_AMUX_THM3_100K_PU>;
		qcom,ratiometric;
		qcom,hw-settle-time = <200>;
		label = "pm8150l_therm";
	};
};

&pm8150l_adc_tm {
	status = "okay";

	skin-msm-therm@0 {
		reg = <0>;
		io-channels = <&pm8150l_adc ADC5_AMUX_THM2_100K_PU>;
		qcom,ratiometric;
		qcom,hw-settle-time-us = <200>;
	};

	pm8150l-therm@1 {
		reg = <1>;
		io-channels = <&pm8150l_adc ADC5_AMUX_THM3_100K_PU>;
		qcom,ratiometric;
		qcom,hw-settle-time-us = <200>;
	};
};

&pm8150l_flash {
	status = "okay";

	led-0 {
		function = LED_FUNCTION_FLASH;
		color = <LED_COLOR_ID_WHITE>;
		led-sources = <1>;
		led-max-microamp = <300000>;
		flash-max-microamp = <1000000>;
		flash-max-timeout-us = <1280000>;
	};

};

&pon_pwrkey {
	status = "okay";
};

&pon_resin {
	linux,code = <KEY_VOLUMEDOWN>;
	status = "okay";
};

&qupv3_id_0 {
	status = "okay";
};

&qupv3_id_1 {
	status = "okay";
};

&qupv3_id_2 {
	status = "okay";
};

&tlmm {
	gpio-reserved-ranges = <28 4>, <40 4>;

	bt_en_state: bt-default-state {
		pins = "gpio21";
		function = "gpio";
		drive-strength = <16>;
		output-low;
		bias-pull-up;
	};

	wlan_en_state: wlan-default-state {
		pins = "gpio20";
		function = "gpio";

		drive-strength = <16>;
		output-low;
		bias-pull-up;
	};

	wlan_en_sleep: wlan-sleep-state {
		pins = "gpio20";
		function = "gpio";

		drive-strength = <16>;
		output-low;
		bias-pull-down;
	};

	panel_reset_pins: panel-reset-state {
		pins = "gpio75";
		function = "gpio";
		drive-strength = <8>;
		bias-disable;
	};

	panel_vsync_pins: panel-vsync-state {
		pins = "gpio66";
		function = "mdp_vsync";
		drive-strength = <16>;
		bias-pull-down;
	};

	panel_vout_pins: panel-vout-state {
		pins = "gpio8";
		function = "gpio";
		drive-strength = <16>;
		output-high;
	};

	panel_avdd_pins: panel-avdd-state {
		pins = "gpio61";
		function = "gpio";
		drive-strength = <8>;
		output-high;
	};

	touch_irq_active: touch-irq-state {
		pins = "gpio39";
		function = "gpio";
		drive-strength = <2>;
		bias-pull-up;
		output-disable;
	};

	touch_rst_active: touch-rst-state {
		pins = "gpio38";
		function = "gpio";
		drive-strength = <8>;
		bias-pull-up;
	};

	spkr_1_sd_active: spkr_1_sd_active {
		pins = "gpio126";
		function = "gpio";
		drive-strength = <16>;
		bias-pull-up;
		output-high;
	};

	spkr_2_sd_active: spkr_2_sd_active {
		pins = "gpio127";
		function = "gpio";
		drive-strength = <16>;
		bias-pull-up;
		output-high;
	};
	
	wcd938x_reset_default: wcd938x-reset-default-state {
		pins = "gpio32";
		function = "gpio";
		drive-strength = <16>;
		output-high;
	};

	wcd938x_reset_sleep: wcd938x-reset-sleep-state {
		pins = "gpio32";
		function = "gpio";
		drive-strength = <16>;
		bias-disable;
		output-low;
	};
	
	cam_main_default: cam-main-default-state {
		mclk0-pins {
			pins = "gpio94";
			function = "cam_mclk";
			bias-disable;
			drive-strength = <2>;
		};
	
		reset-pins {
			pins = "gpio145";
			function = "gpio";
			bias-disable;
			drive-strength = <2>;
		};
	};
    
    cam_main_avdd_default: cam-main-avdd-default {
		pins = "gpio26";
		function = "gpio";
		drive-strength = <2>;
		output-high;
	};
	
	cam_main_avdd2_default: cam-main-avdd2-default {
		pins = "gpio156";
		function = "gpio";
		drive-strength = <16>;
		output-high;
		bias-pull-up;
	};
    
	cam_front_default: cam-front-default-state {
		mclk2-pins {
			pins = "gpio96";
			function = "cam_mclk";
			bias-disable;
			drive-strength = <2>;
		};
	
		reset-pins {
			pins = "gpio90";
			function = "gpio";
			bias-disable;
			drive-strength = <2>;
		};
	};
	
	cam_front_avdd_default: cam-front-avdd-default {
		pins = "gpio24";
		function = "gpio";
		drive-strength = <2>;
		output-high;
	};
};

&uart6 {
	status = "okay";

	bluetooth {
		compatible = "qcom,qca6390-bt";

		vddrfacmn-supply = <&vreg_pmu_rfa_cmn>;
		vddaon-supply = <&vreg_pmu_aon_0p59>;
		vddbtcmx-supply = <&vreg_pmu_btcmx_0p85>;
		vddrfa0p8-supply = <&vreg_pmu_rfa_0p8>;
		vddrfa1p2-supply = <&vreg_pmu_rfa_1p2>;
		vddrfa1p7-supply = <&vreg_pmu_rfa_1p7>;
	};
};

&uart12 {
	status = "okay";
};

&pon {
	mode-bootloader = <0x2>;
	mode-recovery = <0x1>;
};

&ufs_mem_hc {
	status = "okay";

	vcc-supply = <&vreg_l17a_3p0>;
	vcc-max-microamp = <800000>;
	vccq-supply = <&vreg_l6a_1p2>;
	vccq-max-microamp = <800000>;
	vccq2-supply = <&vreg_s4a_1p8>;
	vccq2-max-microamp = <800000>;
};

&ufs_mem_phy {
	status = "okay";

	vdda-phy-supply = <&vreg_l5a_0p88>;
	vdda-pll-supply = <&vreg_l9a_1p2>;
};

&usb_1 {
	status = "okay";
};

&usb_1_dwc3 {
	dr_mode = "otg";
	usb-role-switch;
};

&usb_1_dwc3_hs_out {
	remote-endpoint = <&pm8150b_hs_in>;
};

&usb_1_hsphy {
	status = "okay";

	vdda-pll-supply = <&vreg_l5a_0p88>;
	vdda33-supply = <&vreg_l2a_3p1>;
	vdda18-supply = <&vreg_l12a_1p8>;
};

&usb_1_qmpphy {
	status = "okay";

	vdda-phy-supply = <&vreg_l9a_1p2>;
	vdda-pll-supply = <&vreg_l18a_0p92>;
};

&usb_1_qmpphy_dp_in {
	remote-endpoint = <&mdss_dp_out>;
};

&usb_1_qmpphy_out {
	remote-endpoint = <&pm8150b_typec_mux_in>;
};
